AUTOSAR XML (schema 00053)
package /Application
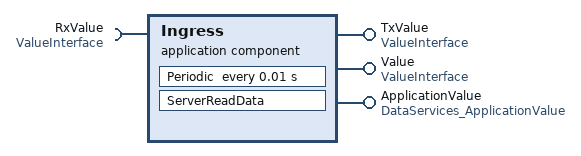
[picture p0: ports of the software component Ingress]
  application sw component type Ingress
    require port RxValue: nonqueued-receiver-com-spec{data-element=Value, alive-timeout=0.03, handle-never-received=true, init-value=0}, required-interface=ValueInterface
    provide port TxValue: nonqueued-sender-com-spec{data-element=Value, init-value=0}, provided-interface=ValueInterface
    provide port Value: nonqueued-sender-com-spec{data-element=Value, init-value=1}, provided-interface=ValueInterface
    provide port ApplicationValue: server-com-spec{operation=ReadData, queue-length=1}, provided-interface=DataServices_ApplicationValue
    behavior Behavior: data-type-mapping=ApplicationTypes
      timing event Periodic10ms: start-on-event=Periodic, period=0.01
      operation invoked event InvokeReadData: start-on-event=ServerReadData, operation=ApplicationValue.ReadData
      runnable Periodic: symbol=Ingress_Periodic
        data-receive-point-by-arguments:
          access RRxValue: accessed-variable=RxValue.Value
        data-send-points:
          access PTxValue: accessed-variable=TxValue.Value
          access PValue: accessed-variable=Value.Value
      runnable ServerReadData: symbol=Ingress_ReadData
